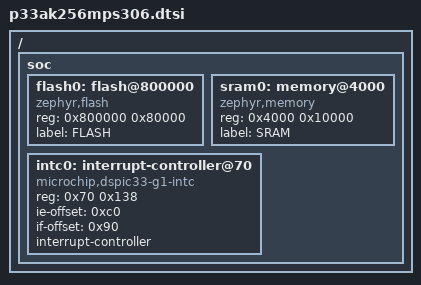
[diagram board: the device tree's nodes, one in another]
/*
 * SPDX-FileCopyrightText: Copyright (c) 2026 Microchip Technology Inc.
 * SPDX-License-Identifier: Apache-2.0
 */

#include <dspic/common/dspic33a.dtsi>

/ {
	soc: soc {
		#address-cells = <1>;
		#size-cells = <1>;

		flash0: flash@800000 {
			compatible = "zephyr,flash";
			reg = <0x800000 0x80000>;
			label = "FLASH";
		};

		sram0: memory@4000 {
			compatible = "zephyr,memory";
			reg = <0x4000 0x10000>;
			label = "SRAM";
		};

		intc0: interrupt-controller@70 {
			compatible = "microchip,dspic33-g1-intc";
			reg = <0x70 0x138>;
			ie-offset = <0xc0>;
			if-offset = <0x90>;
			interrupt-controller;
			#address-cells = <0>;
			#interrupt-cells = <2>;
		};
	};
};
